# Montana register map
Vendor: ONSemiconductor; Series: Montana Series; File version: 1.0
onsemi Montana
CPU: CM33 r0p4, little endian, MPU, FPU, 3 interrupt priority bits
Registers are 32-bit, read-write, reset 0x0 unless marked. A register's access mark holds for its fields unless they carry their own. Offsets are from the block's base; lines under a group give offsets from that group; [hi:lo] are bit positions; {n}, {i} and the like mark numbered series; 'fields as' and 'values as' point back to an identical list; <NAME> marks a mode.

## Memory map
0x1FFFFFFC AHBREGS — AHB registers
0x40000000 SYSCTRL size 0x20090 — System Control
0x40000100 CLK size 0xC — Clock Generation
0x40000200 RESET
0x40000300 WATCHDOG size 0xFC — Watchdog Timer
0x40000400 TIMER0 size 0xFC — General-Purpose Timers
0x40000500 TIMER1 size 0xFC — General-Purpose Timers
0x40000600 TIMER2 size 0xFC — General-Purpose Timers
0x40000700 TIMER3 size 0xFC — General-Purpose Timers
0x40000800 FLASH0 size 0xFC — Flash Interface Configuration and Control
0x40000900 FLASH1 size 0xFC — Flash Interface Configuration and Control
0x40000A00 GPIO size 0x13C — GPIO Interface and Digital Pad control
0x40000C00 SPI size 0xFC — SPI Interface Configuration and Control
0x40000D00 I2C size 0xFC — I2C Interface Configuration and Control
0x40000E00 UART size 0xFC — UART Interface Configuration and Control
0x40000F00 DMA0 size 0xFC — DMA Controller Configuration and Control
0x40001000 DMA1 size 0xFC — DMA Controller Configuration and Control
0x40001100 DMA2 size 0xFC — DMA Controller Configuration and Control
0x40001200 DMA3 size 0xFC — DMA Controller Configuration and Control
0x40001300 CRC size 0xFC — CRC Generator Control
0x40001400 ASCC size 0xFC — Asynchronous Clock Counter
0x40001500 LSAD size 0xFC — Low-Speed ADC
0x40001600 ACS size 0x90 — Analog Control System
0x40001700 SENSOR size 0x68 — Sensor domain (Analog Bridge Access)
0x40001800 BBIF size 0xFC — Baseband Controller Interface
0x40001900 BB size 0x188 — Baseband Controller
0x40001B00 TOF size 0xFC — Time Of Flight Timer
0x40001F00 TESTCTRL size 0x4 — TEST Control Interface
0x40040000 NFC size 0x3C — NFC Controller
0x40040800 RF0 size 0x1FC — RF Front-End 2.4 GHz
0x40040A00 RF1 size 0x1FC — RF Front-End 2.4 GHz
0x40040C00 RF2 size 0x1FC — RF Front-End 2.4 GHz
0x40040E00 RF3 size 0x1FC — RF Front-End 2.4 GHz
0xE000E004 ICB — Implementation Control Block
0xE000E010 SysTick size 0xC — SysTick Timer
0xE000E100 NVIC size 0x20334 — Nested Vector Interrupt Controller
0xE000ED00 SCB size 0x8C — System Control Block
0xE000ED90 MPU size 0x30 — Memory Protection Unit
0xE000EDD0 SAU size 0x18 — Security Attribution Unit
0xE000EDF0 DEBUG size 0x18 — Debug Control Block
0xE000EF00 SIG — Software Interrupt Generation
0xE000EF34 FPE size 0x14 — Floating-Point Extension

## AHBREGS — AHB registers
Base 0x1FFFFFFC
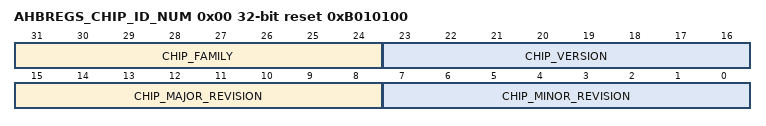
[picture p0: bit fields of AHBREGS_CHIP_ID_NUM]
0x00 AHBREGS_CHIP_ID_NUM ro reset 0xB010100 — Chip ID number
  [31:24] CHIP_FAMILY — Chip Family number
    11=CHIP_FAMILY_NUMBER (BLE family)
  [23:16] CHIP_VERSION — Chip Version number
    1=CHIP_VERSION_NUMBER (Value for SV3 FPGA/SLR)
  [15:8] CHIP_MAJOR_REVISION — Chip Major Revision number
    1=CHIP_MAJOR_REVISION_NUMBER (Value for SV3 FPGA/SLR)
  [7:0] CHIP_MINOR_REVISION — Chip Minor Revision number
    0=CHIP_MINOR_REVISION_NUMBER (Value for SV3 FPGA/SLR)

## CLK — Clock Generation
Base 0x40000100
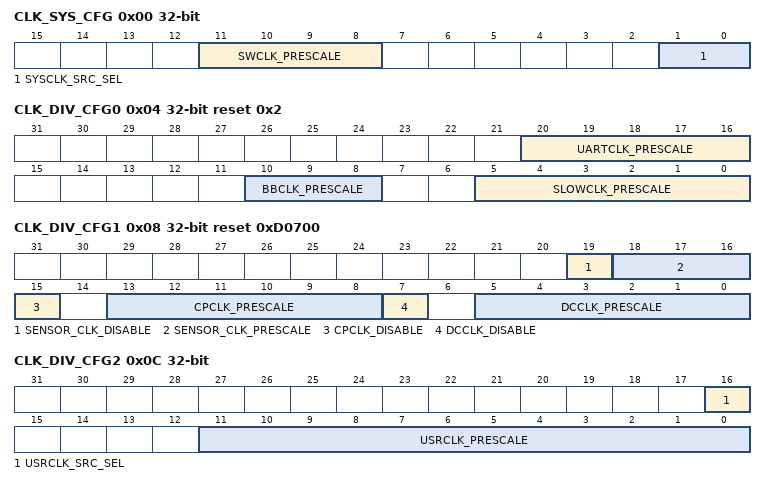
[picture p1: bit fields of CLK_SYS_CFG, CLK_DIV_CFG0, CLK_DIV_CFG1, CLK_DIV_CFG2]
0x00 CLK_SYS_CFG — System Clock Configuration Register
  [11:8] SWCLK_PRESCALE — Prescale value for the input clock from pad SWCLK (1 to 16 in steps of 1)
    0=Divide by 1; 1=Divide by 2; 3=Divide by 4; 7=Divide by 8; 14=Divide by 15; 15=Divide by 16
  [1:0] SYSCLK_SRC_SEL — Controls the source of the system clock : SWCLK, RFCLK, RCCLK, or STANDBYCLK
    0=SYSCLK_CLKSRC_RCCLK (Select the RCCLK clock as SYSCLK clock source); 1=SYSCLK_CLKSRC_STANDBYCLK (Select the STANDBYCLK clock as SYSCLK clock source); 2=SYSCLK_CLKSRC_RFCLK (Select the RFCLK clock as SYSCLK clock source); 3=SYSCLK_CLKSRC_SWCLK (Select the SWCLK clock as SYSCLK clock source)
0x04 CLK_DIV_CFG0 reset 0x2 — Prescale register for SLOWCLK, BBCLK and UARTCLK clocks
  [20:16] UARTCLK_PRESCALE — Prescale value for the UART peripheral clock (1 to 32 in steps of 1)
    0=Divide by 1; 1=Divide by 2; 30=Divide by 31; 31=Divide by 32
  [10:8] BBCLK_PRESCALE — Prescale value for the Baseband peripheral clock (1 to 8 in steps of 1)
    {v}=Divide by {v+1} (v=0..7)
  [5:0] SLOWCLK_PRESCALE — Prescale value for the SLOWCLK clock (1 to 64 in steps of 1)
    {v}=Divide by {v+1} (v=0..3); 5=Divide by 6; 7=Divide by 8; 9=Divide by 10; 11=Divide by 12; 15=Divide by 16; 23=Divide by 24; 47=Divide by 48; 62=Divide by 63; 63=Divide by 64
0x08 CLK_DIV_CFG1 reset 0xD0700 — Prescale register for charge pump clock and sensor clock
  [19] SENSOR_CLK_DISABLE — Sensor clock disable
    0=SENSOR_CLK_ENABLE (Sensor clock enabled); 1=SENSOR_CLK_DISABLE (Sensor clock disabled)
  [18:16] SENSOR_CLK_PRESCALE — Prescale value for the sensor clock
    0=SENSOR_SLOWCLK_DIV1 (Sensor clock = SLOWCLK); 1=SENSOR_SLOWCLK_DIV2 (Sensor clock = SLOWCLK / 2); 2=SENSOR_SLOWCLK_DIV4 (Sensor clock = SLOWCLK / 4); 3=SENSOR_SLOWCLK_DIV8 (Sensor clock = SLOWCLK / 8); 4=SENSOR_SLOWCLK_DIV16 (Sensor clock = SLOWCLK / 16); 5=SENSOR_SLOWCLK_DIV32 (Sensor clock = SLOWCLK / 32); 6=SENSOR_SLOWCLK_DIV64 (Sensor clock = SLOWCLK / 64); 7=SENSOR_SLOWCLK_DIV128 (Sensor clock = SLOWCLK / 128)
  [15] CPCLK_DISABLE — Charge pump clock disable
    0=CPCLK_ENABLE (Charge pump clock enabled); 1=CPCLK_DISABLE (Charge pump clock disabled)
  [13:8] CPCLK_PRESCALE — Prescale value for the charge pump clock from the SLOWCLK clock (1 to 64 in steps of 1)
    {v}=Divide by {v+1} (v=0..9); 62=Divide by 63; 63=Divide by 64
  [7] DCCLK_DISABLE — DC-DC converter clock disable
    0=DCCLK_ENABLE (DC-DC converter clock enabled); 1=DCCLK_DISABLE (DC-DC converter clock disabled)
  [5:0] DCCLK_PRESCALE — Prescale value for the DC-DC converter clock (1 to 64 in steps of 1)
    {v}=Divide by {v+1} (v=0..9); 11=Divide by 12; 62=Divide by 63; 63=Divide by 64
0x0C CLK_DIV_CFG2 — Prescale register for User clock
  [16] USRCLK_SRC_SEL — USR clock source selection
    0=USRCLK_SRC_SYSCLK (User clock based on system clock); 1=USRCLK_SRC_RFCLK (User clock based on RF clock)
  [11:0] USRCLK_PRESCALE — Prescale value for the USR clock (1 to 4096 in steps of 1)
    0=Divide by 1; 1=Divide by 2; 2=Divide by 3; 0xFFE=Divide by 4095; 0xFFF=Divide by 4096

## Licence text in the file
---------------------------------------------------------------------------- Copyright (c) 2021 Semiconductor Components Industries, LLC (d/b/a onsemi), All Rights Reserved This code is the property of onsemi and may not be redistributed in any form without prior written permission from onsemi. The terms of use and warranty for this code are covered by contractual agreements between onsemi and the licensee. This is Reusable Code. ----------------------------------------------------------------------------
